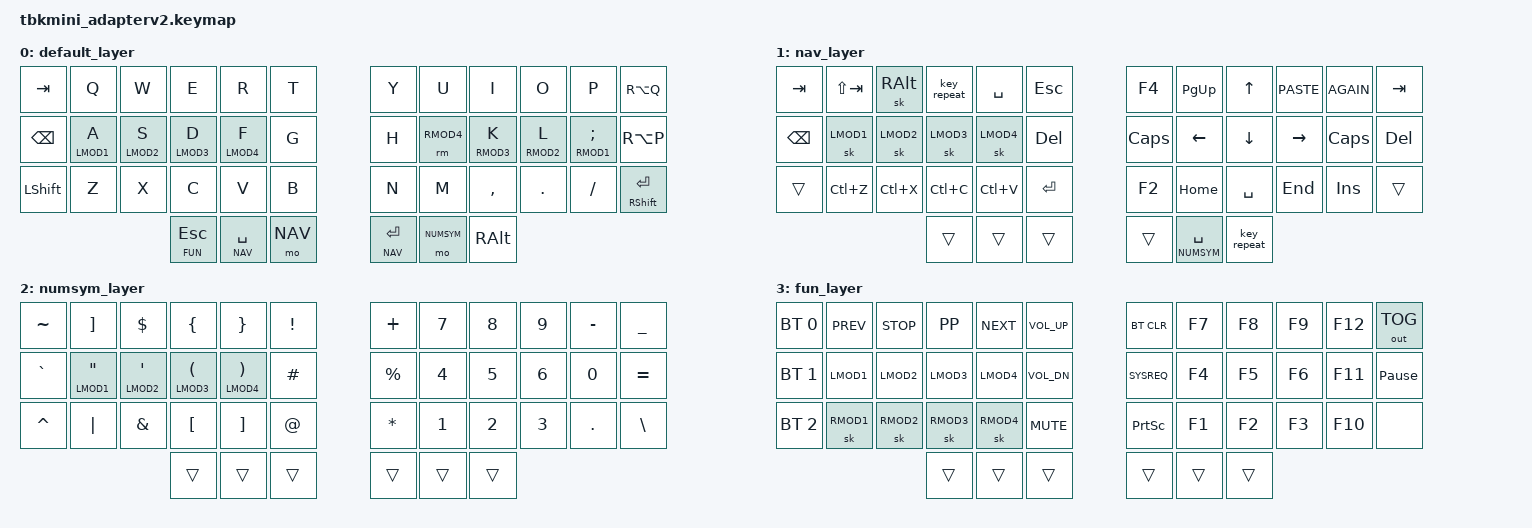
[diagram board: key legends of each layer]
#include <behaviors.dtsi>
#include <dt-bindings/zmk/keys.h>
#include <dt-bindings/zmk/bt.h>
#include <dt-bindings/zmk/outputs.h>

#define DEFAULT 0
#define NAV 1
#define NUMSYM 2
#define FUN 3

// Modifier order
#define LMOD1 LGUI
#define LMOD2 LALT
#define LMOD3 LSHFT
#define LMOD4 LCTRL
#define RMOD4 RCTRL
#define RMOD3 RSHFT
#define RMOD2 LALT
#define RMOD1 RGUI

&lt {
	tapping-term-ms = <300>;
	quick_tap_ms = <200>;
	flavor = "hold-preferred";
};

/ {
	chosen {
		zmk,matrix_transform = &default_transform;
	};

	behaviors {
		hm: homerow_mods {
			compatible = "zmk,behavior-hold-tap";
			label = "HOMEROW_MODS";
			#binding-cells = <2>;
			tapping-term-ms = <150>;
			quick_tap_ms = <150>;
			flavor = "tap-preferred";
			bindings = <&kp>, <&kp>;
		};
		lm: left_hand_positional_hold_tap {
			compatible = "zmk,behavior-hold-tap";
			label = "LEFT_HOMEROW_MODS";
			#binding-cells = <2>;
			flavor = "tap-unless-interrupted";
			tapping-term-ms = <200>;
			quick-tap-ms = <200>;
			bindings = <&kp>, <&kp>;
			hold-trigger-key-positions = <6 7 8 9 10 11  18 19 20 21 22 23  30 31 32 33 34 35>;
		};
		rm: right_hand_positional_hold_tap {
			compatible = "zmk,behavior-hold-tap";
			label = "RIGHT_HOMEROW_MODS";
			#binding-cells = <2>;
			flavor = "tap-unless-interrupted";
			tapping-term-ms = <200>;
			quick-tap-ms = <200>;
			bindings = <&kp>, <&kp>;
			hold-trigger-key-positions = <0 1 2 3 4 5  12 13 14 15 16  24 25 26 27 28 29>;
		};
	};

	// |  0   1   2   3   4   5   |  6   7   8   9   10  11  |
	// |  12  12  14  15  16  17  |  18  19  20  21  22  23  |
	// |  24  25  26  27  28  29  |  30  31  32  33  34  35  |
	// |              36  37  38  |  39  40  41              |

	keymap {
		compatible = "zmk,keymap";

		default_layer {
			bindings = <
	&kp TAB     &kp Q        &kp W       &kp E       &kp R       &kp T    &kp Y &kp U     &kp I       &kp O       &kp P          &kp RA(Q)
	&kp BSPC    &lm LMOD1 A  &lm LMOD2 S &lm LMOD3 D &lm LMOD4 F &kp G    &kp H &rm RMOD4 &rm RMOD3 K &rm RMOD2 L &rm RMOD1 SEMI &kp RA(P)
	&kp LSHFT   &kp Z        &kp X       &kp C       &kp V       &kp B    &kp N &kp M     &kp COMMA   &kp DOT     &kp FSLH       &mt RSHFT RET
	            &lt FUN ESC  &lt NAV SPACE  &mo NAV                       &lt NAV RET &mo NUMSYM  &kp RALT
			>;
		};
		nav_layer {
			bindings = <
	&kp TAB     &kp LS(TAB) &sk RALT  &key_repeat &kp SPACE &kp ESC          &kp F4   &kp PG_UP &kp UP     &kp K_PASTE &kp K_AGAIN &kp TAB
	&kp BSPC    &sk LMOD1   &sk LMOD2 &sk LMOD3   &sk LMOD4 &kp DEL          &kp CAPS &kp LEFT  &kp DOWN   &kp RIGHT   &kp CAPS    &kp DEL
	&trans      &kp LC(Z)   &kp LC(X) &kp LC(C)   &kp LC(V) &kp RET          &kp F2   &kp HOME  &kp SPACE  &kp END     &kp INS     &trans
	                &trans    &trans    &trans                               &trans   &lt NUMSYM SPACE     &key_repeat
			>;
		};
		numsym_layer {
			bindings = <
	&kp TILDE &kp RBKT      &kp DLLR      &kp LBRC       &kp RBRC       &kp EXCL    &kp PLUS  &kp N7  &kp N8  &kp N9  &kp MINUS  &kp UNDER
	&kp GRAVE &hm LMOD1 DQT &hm LMOD2 SQT &hm LMOD3 LPAR &hm LMOD4 RPAR &kp HASH    &kp PRCNT &kp N4  &kp N5  &kp N6  &kp N0     &kp EQUAL
	&kp CARET &kp PIPE      &kp AMPS      &kp LBKT       &kp RBKT       &kp AT      &kp STAR  &kp N1  &kp N2  &kp N3  &kp DOT    &kp BSLH
	                &trans  &trans  &trans                                          &trans    &trans  &trans
			>;
		};
		fun_layer {
			bindings = <
	&bt BT_SEL 0 &kp K_PREV &kp K_STOP &kp K_PP  &kp K_NEXT &kp K_VOL_UP    &bt BT_CLR      &kp F7  &kp F8  &kp F9  &kp F12  &out OUT_TOG
	&bt BT_SEL 1 &kp LMOD1  &kp LMOD2  &kp LMOD3 &kp LMOD4  &kp K_VOL_DN    &kp SYSREQ      &kp F4  &kp F5  &kp F6  &kp F11  &kp PAUSE_BREAK
	&bt BT_SEL 2 &sk RMOD1  &sk RMOD2  &sk RMOD3 &sk RMOD4  &kp K_MUTE      &kp PRINTSCREEN &kp F1  &kp F2  &kp F3  &kp F10  &none
	                &trans  &trans  &trans                                  &trans          &trans  &trans
			>;
		};
	};
};
